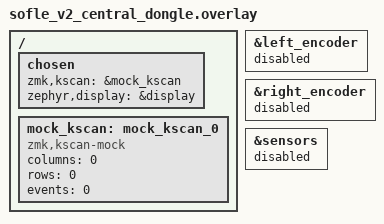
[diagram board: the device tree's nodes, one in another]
#include "sofle_v2.dtsi"
#include <dt-bindings/zmk/matrix_transform.h>

/ {
    chosen {
        zmk,kscan = &mock_kscan;
        zephyr,display = &display;
    };

    mock_kscan: mock_kscan_0 {
        compatible = "zmk,kscan-mock";
        columns = <0>;
        rows = <0>;
        events = <0>;
    };
};

//dongle엔 인코더가 없다.
&left_encoder { status = "disabled"; };
&right_encoder { status = "disabled"; };
&sensors { status = "disabled"; };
